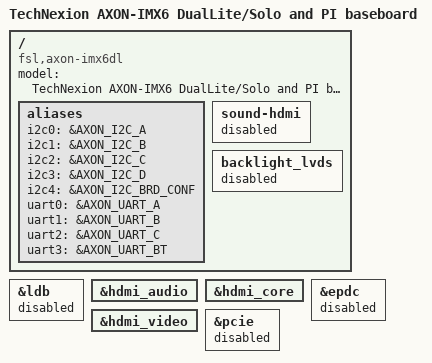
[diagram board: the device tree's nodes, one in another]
/*
 * Copyright 2016,2017,2018 Technexion Ltd.
 *
 * Author: Wig Cheng <wig.cheng@technexion.com>
 *         Richard Hu <richard.hu@technexion.com>
 *         Tapani Utriainen <tapani@technexion.com>
 *
 * This program is free software; you can redistribute it and/or modify
 * it under the terms of the GNU General Public License version 2 as
 * published by the Free Software Foundation.
 *
 */
/dts-v1/;

#include "imx6dl.dtsi"
#include "imx6qdl-axon.dtsi"
#include "baseboard_axon_pi.dtsi"
/ {
	model = "TechNexion AXON-IMX6 DualLite/Solo and PI baseboard";
	compatible = "fsl,axon-imx6dl", "fsl,imx6dl";

	aliases {
		i2c0 = &AXON_I2C_A;
		i2c1 = &AXON_I2C_B;
		i2c2 = &AXON_I2C_C;
		i2c3 = &AXON_I2C_D;
		i2c4 = &AXON_I2C_BRD_CONF;
		uart0 = &AXON_UART_A;
		uart1 = &AXON_UART_B;
		uart2 = &AXON_UART_C;
		uart3 = &AXON_UART_BT;
	};

	sound-hdmi {
		status = "disabled";
	};

	backlight_lvds {
		status = "disabled";
	};
};

&ldb {
	status = "disabled";
};

&hdmi_audio {
	status = "okay";
};

&hdmi_core {
	status = "okay";
};

&hdmi_video {
	status = "okay";
};

&epdc {
	status = "disabled";
};

&pcie {
	status = "disabled";
};
